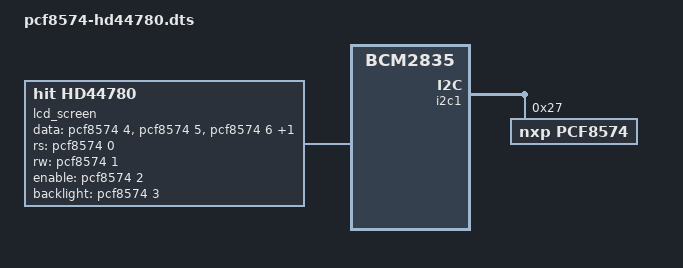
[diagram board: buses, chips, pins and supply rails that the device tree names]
/dts-v1/;
/plugin/;

/ {
    compatible = "brcm,bcm2835";

    fragment@0 {
        target = <&i2c1>;
        __overlay__ {
            #address-cells = <1>;
            #size-cells = <0>;
            status = "okay";

            pcf8574: pcf8574@27 {
                compatible = "nxp,pcf8574";
                reg = <0x27>;		
                gpio-controller;
                #gpio-cells = <2>;
            };
        };
    };

    fragment@1 {
        target-path = "/";
        __overlay__ {
            lcd_screen: auxdisplay {
                compatible = "hit,hd44780";
                status = "okay";

                data-gpios = <&pcf8574 4 0>,
                             <&pcf8574 5 0>,
                             <&pcf8574 6 0>,
                             <&pcf8574 7 0>;
                rs-gpios = <&pcf8574 0 0>;
                rw-gpios = <&pcf8574 1 0>;
                enable-gpios = <&pcf8574 2 0>;
                backlight-gpios = <&pcf8574 3 0>;

                display-height-chars = <2>;
                display-width-chars = <16>;
            };
        };
    };
};

